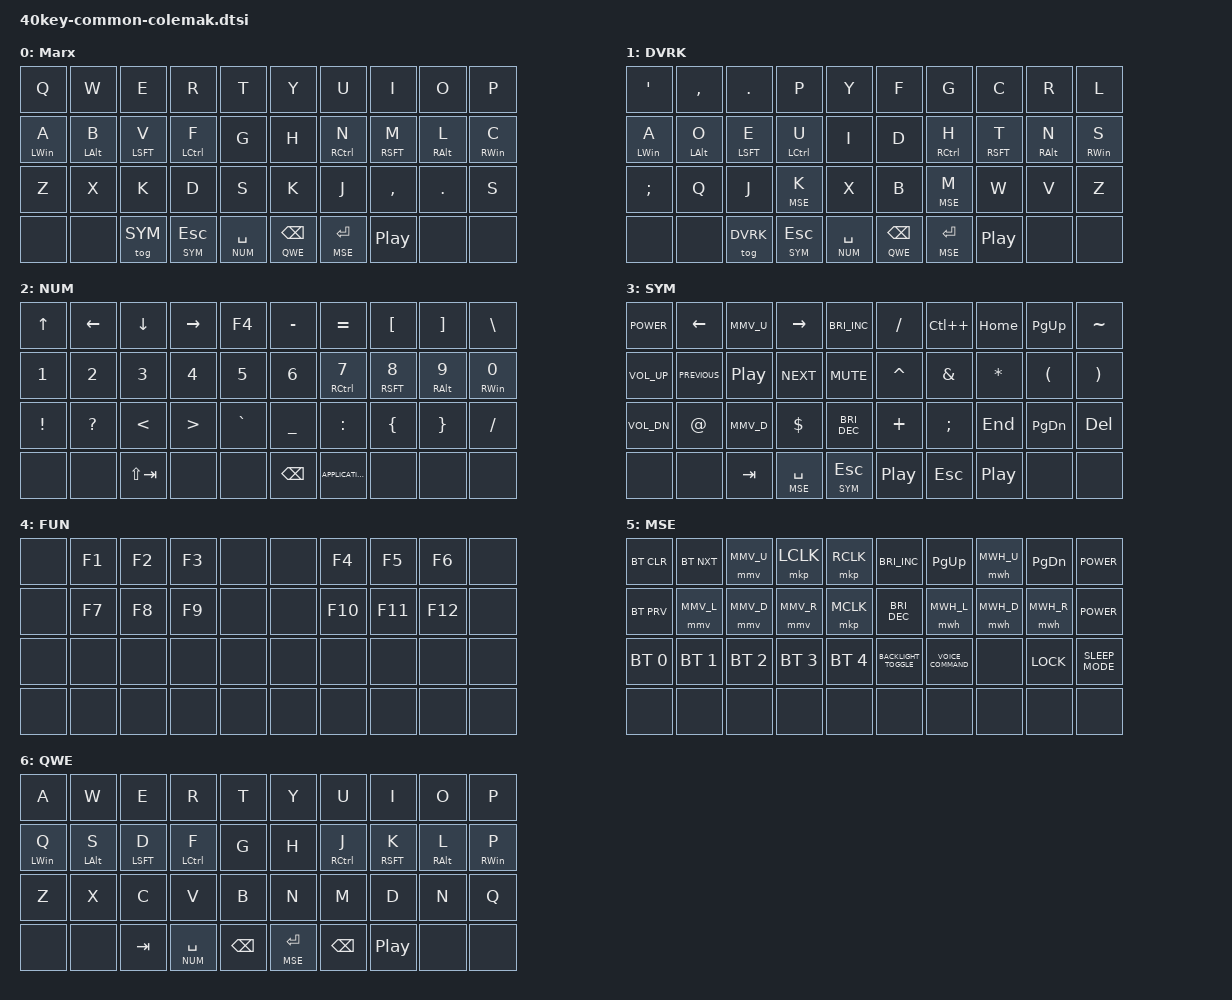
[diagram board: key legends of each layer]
#include <behaviors.dtsi>
#include <dt-bindings/zmk/keys.h>
#include <dt-bindings/zmk/bt.h>
#include <dt-bindings/zmk/outputs.h>
#include <dt-bindings/zmk/mouse.h>

#define DEFAULT 0
#define DVRK    1
#define NUM     2
#define SYM     3
#define FUN     4
#define MSE     5
#define QWE     6


#include "key-common.dtsi"

// mod-tap settings
&mt {
   flavor = "tap-preferred";
   tapping_term_ms = <200>;
};

// mouse move settings
#define MMV_U MOVE_VERT(-1650)
#define MMV_D MOVE_VERT(1650)
#define MMV_L MOVE_HOR(-1650)
#define MMV_R MOVE_HOR(1650)

&mmv {    
        time-to-max-speed-ms = <500>;
        acceleration-exponent=<1>;
};

// mouse wheel settings
#define MWH_U SCROLL_VERT(15)
#define MWH_D SCROLL_VERT(-15)
#define MWH_L SCROLL_HOR(-15)
#define MWH_R SCROLL_HOR(15)

&mwh {    
        time-to-max-speed-ms = <2000>;
        acceleration-exponent=<0>;
};

// keymap definition
/ { 

    keymap {
        compatible = "zmk,keymap";
                
     		default_layer {
            label = "Marx";
			bindings = <
            		&kp Q     &kp W      &kp E      &kp R      &kp T         &kp Y    &kp U      &kp I      &kp O      &kp P
             		&mt LWIN A &mt LALT B &mt LSFT V &mt LCTL F &kp G         &kp H    &mt RCTL N &mt RSFT M &mt RALT L &mt RWIN C 
                &kp Z     &kp X      &kp K      &kp D  &kp S         &kp K    &kp J  &kp COMMA &kp DOT &kp S
                &none  &none  &tog SYM    &lt SYM ESC  &lt NUM SPACE     &lt QWE BSPC  &lt MSE RET  &kp C_PLAY_PAUSE  &none   &none
         		>;
            sensor-bindings = <&inc_dec_kp RIGHT LEFT &inc_dec_kp C_PREVIOUS C_NEXT>;
		    };
		    
		    	dvorak_layer {
            label = "DVRK";
			bindings = <
            	&kp SINGLE_QUOTE     &kp COMMA   &kp DOT   &kp P   &kp Y         &kp F    &kp G     &kp C      &kp R      &kp L
             	&mt LWIN A &mt LALT O &mt LSFT E &mt LCTL U &kp I         &kp D    &mt RCTL H &mt RSFT T &mt RALT N &mt RWIN S 
                &kp SEMI    &kp Q      &kp J      &lt MSE K  &kp X         &kp B    &lt MSE M  &kp W &kp V &kp Z
                &none  &none  &tog DVRK  &lt SYM ESC  &lt NUM SPACE       &lt QWE BSPC  &lt MSE RET  &kp C_PLAY_PAUSE  &none   &none
         		>;
            sensor-bindings = <&inc_dec_kp RIGHT LEFT &inc_dec_kp C_PREVIOUS C_NEXT>;
		    };

        number_layer {
            label = "NUM";
            bindings = <
                &kp UP  &kp LEFT  &kp DOWN   &kp RIGHT   &kp F4      &kp MINUS    &kp EQUAL  &kp LEFT_BRACKET  &kp RIGHT_BRACKET  &kp BACKSLASH
                &kp N1  &kp N2  &kp N3  &kp N4  &kp N5                &kp N6   &mt RCTL N7  &mt RSFT N8  &mt RALT N9  &mt RWIN N0
                &kp EXCLAMATION  &kp QUESTION  &kp LESS_THAN   &kp GREATER_THAN   &kp GRAVE     &kp UNDERSCORE   &kp COLON  &kp LEFT_BRACE  &kp RIGHT_BRACE  &kp SLASH
                           &none  &none  &kp LS(TAB)  &none  &none     &kp BSPC   &kp K_APPLICATION  &none  &none  &none
            >;
            sensor-bindings = <&inc_dec_kp PG_UP PG_DN &inc_dec_kp C_VOL_UP C_VOL_DN>;
        };

        symbol_layer {
            label = "SYM";
            bindings = <
                &kp C_POWER    &kp LEFT       &kp MMV_U         &kp RIGHT   &kp C_BRIGHTNESS_INC      &kp SLASH  &kp LC(PLUS)  &kp HOME  &kp PAGE_UP  &kp TILDE
                &kp C_VOL_UP   &kp C_PREVIOUS &kp C_PLAY_PAUSE  &kp C_NEXT  &kp C_MUTE                &kp CARET &kp AMPS &kp STAR &kp LPAR &kp RPAR
                &kp C_VOL_DN   &kp AT         &kp MMV_D          &kp DLLR    &kp C_BRIGHTNESS_DEC       &kp PLUS  &kp SEMICOLON   &kp END  &kp PAGE_DOWN  &kp DELETE  
                             &none  &none  &kp TAB  &lt MSE SPACE  &lt SYM ESC       &kp C_PLAY_PAUSE  &kp ESC  &kp C_PLAY_PAUSE  &none  &none
            >;
            sensor-bindings = <&inc_dec_kp RIGHT LEFT &inc_dec_kp C_PREVIOUS C_NEXT>;
        };

        function_layer {
            label = "FUN";
            bindings = <
                &none  &kp F1  &kp F2  &kp F3  &none       &none &kp F4  &kp F5  &kp F6  &none
                &none  &kp F7  &kp F8  &kp F9  &none       &none &kp F10 &kp F11 &kp F12 &none
                &none  &none   &none   &none   &none       &none &none   &none   &none   &none
                &none  &none   &none   &none   &none       &none &none   &none   &none   &none
            >;
            sensor-bindings = <&inc_dec_kp PG_UP PG_DN &inc_dec_kp C_VOL_UP C_VOL_DN>;
        };
        
        mouse_layer {
            label = "MSE";
            bindings = <
                &bt BT_CLR  &bt BT_NXT       &mmv MMV_U  &mkp LCLK     &mkp RCLK             &kp C_BRIGHTNESS_INC  &kp PAGE_UP   &mwh MWH_U  &kp PAGE_DOWN    &kp C_POWER
                &bt BT_PRV  &mmv MMV_L  &mmv MMV_D  &mmv MMV_R  &mkp MCLK                  &kp C_BRIGHTNESS_DEC  &mwh MWH_L  &mwh MWH_D  &mwh MWH_R  &kp K_POWER
                &bt BT_SEL 0 &bt BT_SEL 1 &bt BT_SEL 2 &bt BT_SEL 3 &bt BT_SEL 4      &kp C_BACKLIGHT_TOGGLE  &kp C_VOICE_COMMAND       &none       &kp K_LOCK       &kp C_SLEEP_MODE
                &none  &none       &none       &none       &none       &none  &none       &none       &none       &none
            >;
            sensor-bindings = <&inc_dec_kp PG_UP PG_DN &inc_dec_kp C_VOL_UP C_VOL_DN>;
        };
	
	cangjie_layer {
            label = "QWE";
			bindings = <
            		&kp A     &kp W      &kp E      &kp R      &kp T         &kp Y    &kp U      &kp I      &kp O      &kp P
             		&mt LWIN Q &mt LALT S &mt LSFT D &mt LCTL F &kp G         &kp H    &mt RCTL J &mt RSFT K &mt RALT L &mt RWIN P 
                &kp Z     &kp X      &kp C      &kp V  &kp B         &kp N    &kp M  &kp D &kp N &kp Q
                &none  &none  &kp TAB  &lt NUM SPACE  &kp BSPC         &lt MSE RET &kp BSPC &kp C_PLAY_PAUSE  &none   &none
         		>;
            sensor-bindings = <&inc_dec_kp DOWN UP &inc_dec_kp C_PREVIOUS C_NEXT>;
		    };

	
   	};
};
